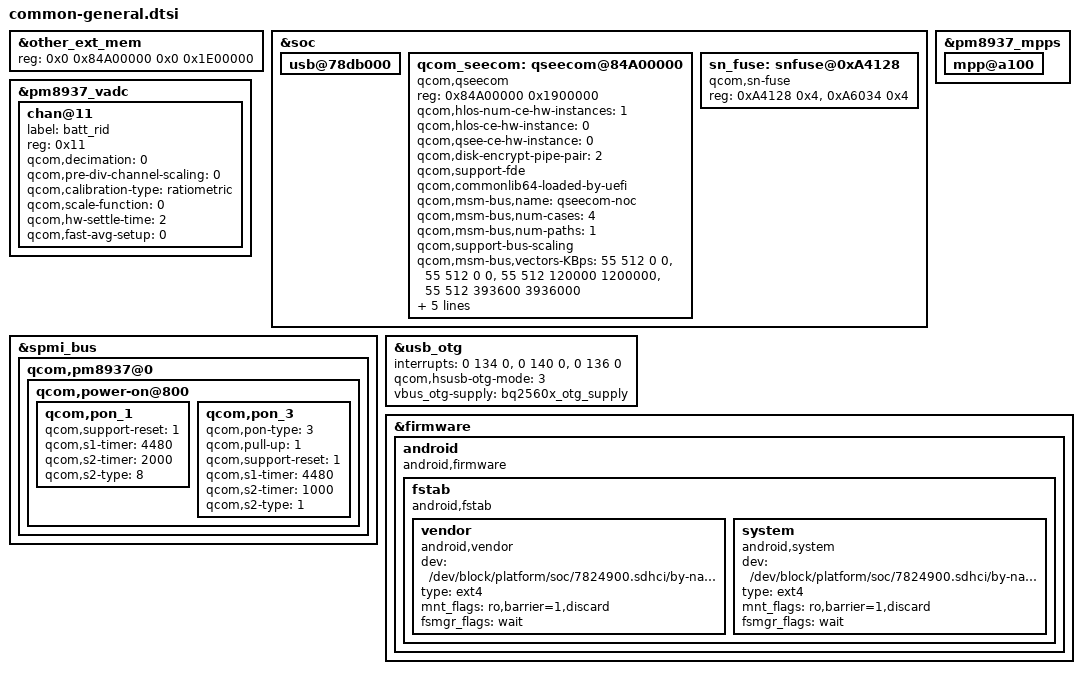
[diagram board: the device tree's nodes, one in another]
/*
 * Copyright (c) 2015, The Linux Foundation. All rights reserved.
 * Copyright (C) 2018 XiaoMi, Inc.
 *
 * This program is free software; you can redistribute it and/or modify
 * it under the terms of the GNU General Public License version 2 and
 * only version 2 as published by the Free Software Foundation.
 *
 * This program is distributed in the hope that it will be useful,
 * but WITHOUT ANY WARRANTY; without even the implied warranty of
 * MERCHANTABILITY or FITNESS FOR A PARTICULAR PURPOSE.  See the
 * GNU General Public License for more details.
 */

&other_ext_mem {
	reg = <0x0 0x84A00000 0x0 0x1E00000>;
};

&soc {
	/delete-node/ pericom-type-c@1d;
	/delete-node/ qseecom@85b00000;

	usb@78db000 {
		/delete-property/ vbus_otg-supply;
	};

	qcom_seecom: qseecom@84A00000 {
		compatible = "qcom,qseecom";
		reg = <0x84A00000 0x1900000>;
		reg-names = "secapp-region";
		qcom,hlos-num-ce-hw-instances = <1>;
		qcom,hlos-ce-hw-instance = <0>;
		qcom,qsee-ce-hw-instance = <0>;
		qcom,disk-encrypt-pipe-pair = <2>;
		qcom,support-fde;
		qcom,commonlib64-loaded-by-uefi;
		qcom,msm-bus,name = "qseecom-noc";
		qcom,msm-bus,num-cases = <4>;
		qcom,msm-bus,num-paths = <1>;
		qcom,support-bus-scaling;
		qcom,msm-bus,vectors-KBps =
			<55 512 0 0>,
			<55 512 0 0>,
			<55 512 120000 1200000>,
			<55 512 393600 3936000>;
		clocks = <&clock_gcc clk_crypto_clk_src>,
			 <&clock_gcc clk_gcc_crypto_clk>,
			 <&clock_gcc clk_gcc_crypto_ahb_clk>,
			 <&clock_gcc clk_gcc_crypto_axi_clk>;
		clock-names = "core_clk_src", "core_clk",
				"iface_clk", "bus_clk";
		qcom,ce-opp-freq = <100000000>;
	};

	sn_fuse: snfuse@0xA4128 {
		compatible = "qcom,sn-fuse";
		reg = <0xA4128 0x4>,
			 <0xA6034 0x4>;
		reg-names = "sn-base","fuse-state";
	};
};

&pm8937_mpps {
	mpp@a100 { /*MPP_02 for ADC*/
		status = "okay";
	};
};

&pm8937_vadc {
	chan@11 {
		label = "batt_rid";
		reg = <0x11>;
		qcom,decimation = <0>;
		qcom,pre-div-channel-scaling = <0>;
		qcom,calibration-type = "ratiometric";
		qcom,scale-function = <0>;
		qcom,hw-settle-time = <2>;
		qcom,fast-avg-setup = <0>;
		/delete-property/ qcom,vadc-thermal-node;
		status = "okay";
	};
};

&spmi_bus {
	qcom,pm8937@0 {
		qcom,power-on@800 {
			qcom,pon_1 {
				qcom,support-reset = <1>;
				qcom,s1-timer = <4480>;
				qcom,s2-timer = <2000>;
				qcom,s2-type = <8>;
			};
			qcom,pon_3 {
				qcom,pon-type = <3>;
				qcom,pull-up = <1>;
				qcom,support-reset = <1>;
				qcom,s1-timer = <4480>;
				qcom,s2-timer = <1000>;
				qcom,s2-type = <1>;
			};
		};
	};
};

&usb_otg{
	interrupts = <0 134 0>,<0 140 0>,<0 136 0>;
	interrupt-names = "core_irq", "async_irq","phy_irq";

	qcom,hsusb-otg-mode = <3>;
	vbus_otg-supply = <&bq2560x_otg_supply>;
};

&firmware {
	android {
		compatible = "android,firmware";
		fstab {
			compatible = "android,fstab";
			vendor {
				compatible = "android,vendor";
				dev = "/dev/block/platform/soc/7824900.sdhci/by-name/cust";
 				type = "ext4";
				mnt_flags = "ro,barrier=1,discard";                              	
				fsmgr_flags = "wait";
                               	status = "ok";
			};

			system {
				compatible = "android,system";
				dev = "/dev/block/platform/soc/7824900.sdhci/by-name/system";
				type = "ext4";
				mnt_flags = "ro,barrier=1,discard";
				fsmgr_flags = "wait";
				status = "ok";
			};
		};
	};
};
